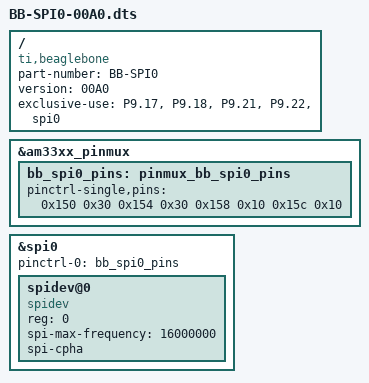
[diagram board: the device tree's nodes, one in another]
/dts-v1/;
/plugin/;

/*
 * BeagleBone Black SPI0 Overlay
 * Enables SPI0 bus on pins P9.17, P9.18, P9.21, P9.22
 */

/ {
    compatible = "ti,beaglebone", "ti,beaglebone-black";
    
    /* identification */
    part-number = "BB-SPI0";
    version = "00A0";
    
    /* state the resources this cape uses */
    exclusive-use =
        /* the pin header uses */
        "P9.17",    /* spi0_cs0 */
        "P9.18",    /* spi0_d1  */
        "P9.21",    /* spi0_d0  */
        "P9.22",    /* spi0_sclk */
        /* the hardware IP uses */
        "spi0";

    fragment@0 {
        target = <&am33xx_pinmux>;
        __overlay__ {
            bb_spi0_pins: pinmux_bb_spi0_pins {
                pinctrl-single,pins = <
                    0x150 0x30  /* P9_22: spi0_sclk, MODE0 | INPUT_PULLUP */
                    0x154 0x30  /* P9_21: spi0_d0,   MODE0 | INPUT_PULLUP */
                    0x158 0x10  /* P9_18: spi0_d1,   MODE0 | OUTPUT_PULLUP */
                    0x15c 0x10  /* P9_17: spi0_cs0,  MODE0 | OUTPUT_PULLUP */
                >;
            };
        };
    };

    fragment@1 {
        target = <&spi0>;
        __overlay__ {
            status = "okay";
            pinctrl-names = "default";
            pinctrl-0 = <&bb_spi0_pins>;
            
            #address-cells = <1>;
            #size-cells = <0>;
            
            spidev@0 {
                compatible = "spidev";
                reg = <0>;
                spi-max-frequency = <16000000>;
                spi-cpha;
            };
        };
    };
};
